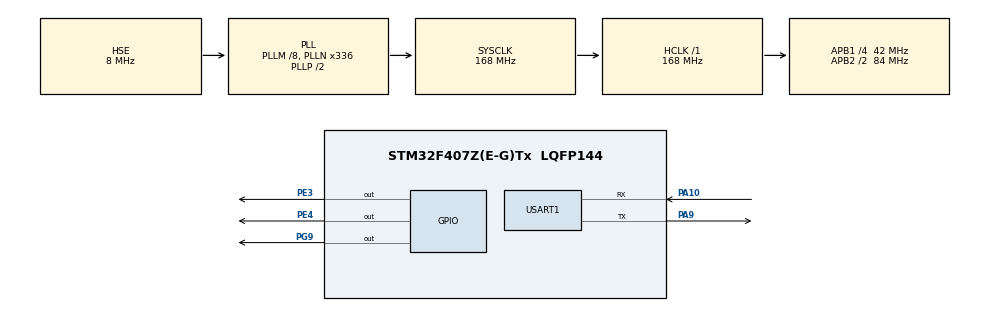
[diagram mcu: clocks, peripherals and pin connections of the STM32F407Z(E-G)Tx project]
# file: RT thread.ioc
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Mcu.Family=STM32F4
Mcu.Name=STM32F407Z(E-G)Tx
Mcu.Package=LQFP144
NVIC.PriorityGroup=NVIC_PRIORITYGROUP_4
NVIC.TIM1_UP_TIM10_IRQn=true\:15\:0\:false\:false\:true\:false\:false\:true
NVIC.TimeBase=TIM1_UP_TIM10_IRQn
NVIC.TimeBaseIP=TIM1
PA10.Mode=Asynchronous
PA10.Signal=USART1_RX
PA13.Mode=Serial_Wire
PA13.Signal=SYS_JTMS-SWDIO
PA14.Mode=Serial_Wire
PA14.Signal=SYS_JTCK-SWCLK
PA9.Mode=Asynchronous
PA9.Signal=USART1_TX
PE3.Signal=GPIO_Output
PE4.Signal=GPIO_Output
PG9.Signal=GPIO_Output
PH0-OSC_IN.Mode=HSE-External-Oscillator
PH0-OSC_IN.Signal=RCC_OSC_IN
PH1-OSC_OUT.Mode=HSE-External-Oscillator
PH1-OSC_OUT.Signal=RCC_OSC_OUT
ProjectManager.HeapSize=0x200
ProjectManager.StackSize=0x400
ProjectManager.TargetToolchain=MDK-ARM V5
RCC.48MHZClocksFreq_Value=84000000
RCC.AHBFreq_Value=168000000
RCC.APB1CLKDivider=RCC_HCLK_DIV4
RCC.APB1Freq_Value=42000000
RCC.APB1TimFreq_Value=84000000
RCC.APB2CLKDivider=RCC_HCLK_DIV2
RCC.APB2Freq_Value=84000000
RCC.APB2TimFreq_Value=168000000
RCC.CortexFreq_Value=168000000
RCC.HCLKFreq_Value=168000000
RCC.HSE_VALUE=8000000
RCC.HSI_VALUE=16000000
RCC.LSE_VALUE=32768
RCC.PLLM=8
RCC.PLLN=336
RCC.PLLSourceVirtual=RCC_PLLSOURCE_HSE
RCC.SYSCLKFreq_VALUE=168000000
RCC.SYSCLKSource=RCC_SYSCLKSOURCE_PLLCLK
RCC.VCOOutputFreq_Value=336000000
RealThread.RT-Thread.3.1.5.RTOSJjkernel=true
RealThread.RT-Thread.3.1.5.RTOSJjshell=true
RealThread.RT-Thread.3.1.5.RT_DEBUG=1
RealThread.RT-Thread.3.1.5.RT_DEBUG_INIT=1
RealThread.RT-Thread.3.1.5.RT_USING_HEAP=1
RealThread.RT-Thread.3.1.5.RT_USING_OVERFLOW_CHECK=1
RealThread.RT-Thread.3.1.5.RT_USING_TIMER_SOFT=1
USART1.VirtualMode=VM_ASYNC
VP_RealThread.RT-Thread_VS_RTOSJjkernel_3.1.5_3.1.5.Mode=RTOSJjkernel
VP_RealThread.RT-Thread_VS_RTOSJjshell_3.1.5_3.1.5.Mode=RTOSJjshell
VP_SYS_VS_tim1.Mode=TIM1
board=custom

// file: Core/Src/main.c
/* USER CODE BEGIN Header */
/**
  ******************************************************************************
  * @file           : main.c
  * @brief          : Main program body
  ******************************************************************************
  * @attention
  *
  * <h2><center>&copy; Copyright (c) 2022 STMicroelectronics.
  * All rights reserved.</center></h2>
  *
  * This software component is licensed by ST under Ultimate Liberty license
  * SLA0044, the "License"; You may not use this file except in compliance with
  * the License. You may obtain a copy of the License at:
  *                             www.st.com/SLA0044
  *
  ******************************************************************************
  */
/* USER CODE END Header */
#include "main.h"
#include "usart.h"
#include "gpio.h"

/* USER CODE BEGIN Includes */
#include <rtthread.h>
#include "RT_Thread_Init.h"

/* USER CODE END Includes */

int main(void)
{

	MX_GPIO_Init();
	MX_USART1_UART_Init();
	if (RT_NULL == Start_thread())
		rt_kprintf("thread is created;\n");

  /* USER CODE END 3 */
}

void SystemClock_Config(void)
{
  RCC_OscInitTypeDef RCC_OscInitStruct = {0};
  RCC_ClkInitTypeDef RCC_ClkInitStruct = {0};

  /** Configure the main internal regulator output voltage
  */
  __HAL_RCC_PWR_CLK_ENABLE();
  __HAL_PWR_VOLTAGESCALING_CONFIG(PWR_REGULATOR_VOLTAGE_SCALE1);
  /** Initializes the RCC Oscillators according to the specified parameters
  * in the RCC_OscInitTypeDef structure.
  */
  RCC_OscInitStruct.OscillatorType = RCC_OSCILLATORTYPE_HSE;
  RCC_OscInitStruct.HSEState = RCC_HSE_ON;
  RCC_OscInitStruct.PLL.PLLState = RCC_PLL_ON;
  RCC_OscInitStruct.PLL.PLLSource = RCC_PLLSOURCE_HSE;
  RCC_OscInitStruct.PLL.PLLM = 8;
  RCC_OscInitStruct.PLL.PLLN = 336;
  RCC_OscInitStruct.PLL.PLLP = RCC_PLLP_DIV2;
  RCC_OscInitStruct.PLL.PLLQ = 4;
  if (HAL_RCC_OscConfig(&RCC_OscInitStruct) != HAL_OK)
  {
    Error_Handler();
  }
  /** Initializes the CPU, AHB and APB buses clocks
  */
  RCC_ClkInitStruct.ClockType = RCC_CLOCKTYPE_HCLK|RCC_CLOCKTYPE_SYSCLK
                              |RCC_CLOCKTYPE_PCLK1|RCC_CLOCKTYPE_PCLK2;
  RCC_ClkInitStruct.SYSCLKSource = RCC_SYSCLKSOURCE_PLLCLK;
  RCC_ClkInitStruct.AHBCLKDivider = RCC_SYSCLK_DIV1;
  RCC_ClkInitStruct.APB1CLKDivider = RCC_HCLK_DIV4;
  RCC_ClkInitStruct.APB2CLKDivider = RCC_HCLK_DIV2;

  if (HAL_RCC_ClockConfig(&RCC_ClkInitStruct, FLASH_LATENCY_5) != HAL_OK)
  {
    Error_Handler();
  }
}

void HAL_TIM_PeriodElapsedCallback(TIM_HandleTypeDef *htim)
{
  if (htim->Instance == TIM1) {
    HAL_IncTick();
  }
}

void Error_Handler(void)
{
  __disable_irq();
  while (1)
  {
  }
}

/************************ (C) COPYRIGHT STMicroelectronics *****END OF FILE****/
